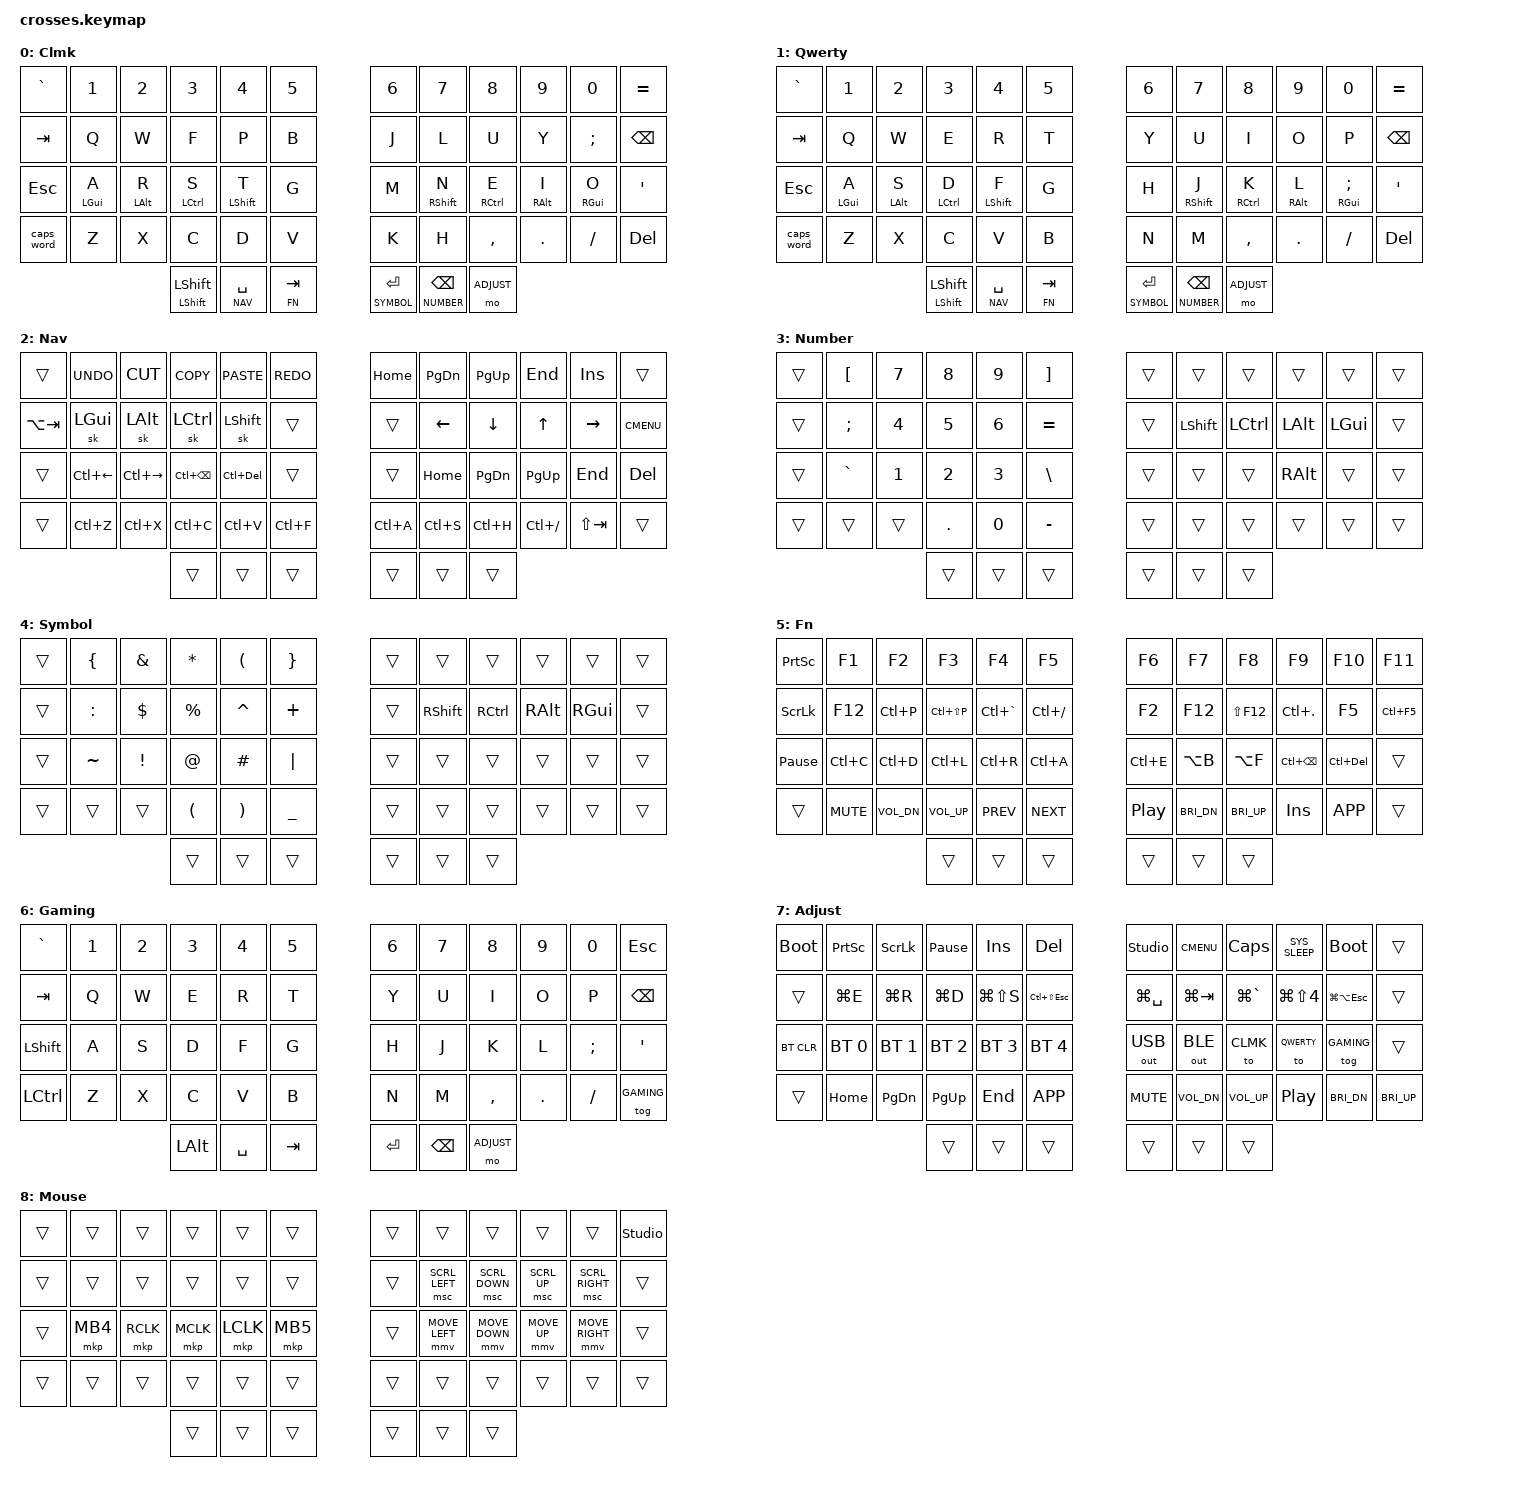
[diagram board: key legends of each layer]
#include <behaviors.dtsi>
#include <dt-bindings/zmk/bt.h>
#include <dt-bindings/zmk/keys.h>
#include <dt-bindings/zmk/outputs.h>
#include <dt-bindings/zmk/pointing.h>

#define CLMK 0
#define QWERTY 1
#define NAV 2
#define NUMBER 3
#define SYMBOL 4
#define FN 5
#define GAMING 6
#define ADJUST 7
#define MOUSE 8

#define ___ &trans
#define XXX &none

&caps_word {
    continue-list = <MINUS UNDERSCORE BACKSPACE DELETE>;
};

&lt {
    flavor = "balanced";
    tapping-term-ms = <200>;
    quick-tap-ms = <175>;
};

&mt {
    flavor = "tap-preferred";
    tapping-term-ms = <220>;
    quick-tap-ms = <175>;
};

&sk {
    release-after-ms = <900>;
    quick-release;
};

/ {
    behaviors {
        hml: homerow_mod_left {
            compatible = "zmk,behavior-hold-tap";
            #binding-cells = <2>;
            flavor = "balanced";
            tapping-term-ms = <220>;
            quick-tap-ms = <175>;
            require-prior-idle-ms = <150>;
            hold-trigger-on-release;
            bindings = <&kp>, <&kp>;
            hold-trigger-key-positions = <6 7 8 9 10 11 18 19 20 21 22 23 30 31 32 33 34 35 42 43 44 45 46 47 51 52 53>;
        };

        hmr: homerow_mod_right {
            compatible = "zmk,behavior-hold-tap";
            #binding-cells = <2>;
            flavor = "balanced";
            tapping-term-ms = <220>;
            quick-tap-ms = <175>;
            require-prior-idle-ms = <150>;
            hold-trigger-on-release;
            bindings = <&kp>, <&kp>;
            hold-trigger-key-positions = <0 1 2 3 4 5 12 13 14 15 16 17 24 25 26 27 28 29 36 37 38 39 40 41 48 49 50>;
        };

        magic_shift: magic_shift {
            compatible = "zmk,behavior-hold-tap";
            #binding-cells = <2>;
            flavor = "balanced";
            tapping-term-ms = <200>;
            quick-tap-ms = <175>;
            bindings = <&kp>, <&sk>;
        };
    };

    chosen { zmk,physical-layout = &gggw_crosses_54_layout; };

    keymap {
        compatible = "zmk,keymap";

        clmk_layer {
            display-name = "Clmk";
            bindings = <
                &kp GRAVE      &kp N1        &kp N2        &kp N3        &kp N4          &kp N5        &kp N6       &kp N7          &kp N8        &kp N9       &kp N0         &kp EQUAL
                &kp TAB        &kp Q         &kp W         &kp F         &kp P           &kp B         &kp J        &kp L           &kp U         &kp Y        &kp SEMI       &kp BSPC
                &kp ESC        &hml LGUI A   &hml LALT R   &hml LCTRL S  &hml LSHFT T    &kp G         &kp M        &hmr RSHFT N    &hmr RCTRL E  &hmr RALT I  &hmr RGUI O    &kp SQT
                &caps_word     &kp Z         &kp X         &kp C         &kp D           &kp V         &kp K        &kp H           &kp COMMA     &kp DOT      &kp FSLH       &kp DEL
                                                            &magic_shift LSHFT LSHFT     &lt NAV SPACE &lt FN TAB   &lt SYMBOL RET  &lt NUMBER BSPC &mo ADJUST
            >;
        };

        qwerty_layer {
            display-name = "Qwerty";
            bindings = <
                &kp GRAVE      &kp N1        &kp N2        &kp N3        &kp N4          &kp N5        &kp N6       &kp N7          &kp N8        &kp N9       &kp N0         &kp EQUAL
                &kp TAB        &kp Q         &kp W         &kp E         &kp R           &kp T         &kp Y        &kp U           &kp I         &kp O        &kp P          &kp BSPC
                &kp ESC        &hml LGUI A   &hml LALT S   &hml LCTRL D  &hml LSHFT F    &kp G         &kp H        &hmr RSHFT J    &hmr RCTRL K  &hmr RALT L  &hmr RGUI SEMI &kp SQT
                &caps_word     &kp Z         &kp X         &kp C         &kp V           &kp B         &kp N        &kp M           &kp COMMA     &kp DOT      &kp FSLH       &kp DEL
                                                            &magic_shift LSHFT LSHFT     &lt NAV SPACE &lt FN TAB   &lt SYMBOL RET  &lt NUMBER BSPC &mo ADJUST
            >;
        };

        nav_layer {
            display-name = "Nav";
            bindings = <
                ___            &kp K_UNDO    &kp K_CUT     &kp K_COPY    &kp K_PASTE     &kp K_REDO    &kp HOME     &kp PG_DN       &kp PG_UP     &kp END      &kp INS        ___
                &kp LA(TAB)    &sk LGUI      &sk LALT      &sk LCTRL     &sk LSHFT       ___           ___          &kp LEFT        &kp DOWN      &kp UP       &kp RIGHT      &kp K_CMENU
                ___            &kp LC(LEFT)  &kp LC(RIGHT) &kp LC(BSPC)  &kp LC(DEL)     ___           ___          &kp HOME        &kp PG_DN     &kp PG_UP    &kp END        &kp DEL
                ___            &kp LC(Z)     &kp LC(X)     &kp LC(C)     &kp LC(V)       &kp LC(F)     &kp LC(A)    &kp LC(S)       &kp LC(H)     &kp LC(FSLH) &kp LS(TAB)    ___
                                                            ___                       ___           ___          ___             ___           ___
            >;
        };

        number_layer {
            display-name = "Number";
            bindings = <
                ___            &kp LBKT      &kp N7        &kp N8        &kp N9          &kp RBKT      ___          ___            ___          ___         ___            ___
                ___            &kp SEMI      &kp N4        &kp N5        &kp N6          &kp EQUAL     ___          &kp LSHFT      &kp LCTRL    &kp LALT    &kp LGUI       ___
                ___            &kp GRAVE     &kp N1        &kp N2        &kp N3          &kp BSLH      ___          ___            ___          &kp RALT    ___            ___
                ___            ___           ___           &kp DOT       &kp N0          &kp MINUS     ___          ___            ___          ___         ___            ___
                                                            ___                       ___           ___          ___             ___           ___
            >;
        };

        symbol_layer {
            display-name = "Symbol";
            bindings = <
                ___            &kp LBRC      &kp AMPS      &kp ASTRK     &kp LPAR        &kp RBRC      ___          ___            ___          ___         ___            ___
                ___            &kp COLON     &kp DLLR      &kp PRCNT     &kp CARET       &kp PLUS      ___          &kp RSHFT      &kp RCTRL    &kp RALT    &kp RGUI       ___
                ___            &kp TILDE     &kp EXCL      &kp AT        &kp HASH        &kp PIPE      ___          ___            ___          ___         ___            ___
                ___            ___           ___           &kp LPAR      &kp RPAR        &kp UNDER     ___          ___            ___          ___         ___            ___
                                                            ___                       ___           ___          ___             ___           ___
            >;
        };

        fn_layer {
            display-name = "Fn";
            bindings = <
                &kp PSCRN      &kp F1        &kp F2        &kp F3        &kp F4          &kp F5        &kp F6       &kp F7         &kp F8       &kp F9      &kp F10        &kp F11
                &kp SLCK       &kp F12       &kp LC(P)     &kp LC(LS(P)) &kp LC(GRAVE)   &kp LC(FSLH)  &kp F2       &kp F12        &kp LS(F12)  &kp LC(DOT) &kp F5         &kp LC(F5)
                &kp PAUSE_BREAK &kp LC(C)    &kp LC(D)     &kp LC(L)     &kp LC(R)       &kp LC(A)     &kp LC(E)    &kp LA(B)      &kp LA(F)    &kp LC(BSPC)&kp LC(DEL)    ___
                ___            &kp C_MUTE    &kp C_VOL_DN  &kp C_VOL_UP  &kp C_PREV      &kp C_NEXT    &kp C_PLAY_PAUSE &kp C_BRI_DN &kp C_BRI_UP &kp INS     &kp K_APP      ___
                                                            ___                       ___           ___          ___             ___           ___
            >;
        };

        gaming_layer {
            display-name = "Gaming";
            bindings = <
                &kp GRAVE      &kp N1        &kp N2        &kp N3        &kp N4          &kp N5        &kp N6       &kp N7         &kp N8       &kp N9      &kp N0         &kp ESC
                &kp TAB        &kp Q         &kp W         &kp E         &kp R           &kp T         &kp Y        &kp U          &kp I        &kp O       &kp P          &kp BSPC
                &kp LSHFT      &kp A         &kp S         &kp D         &kp F           &kp G         &kp H        &kp J          &kp K        &kp L       &kp SEMI       &kp SQT
                &kp LCTRL      &kp Z         &kp X         &kp C         &kp V           &kp B         &kp N        &kp M          &kp COMMA    &kp DOT     &kp FSLH       &tog GAMING
                                                            &kp LALT                  &kp SPACE     &kp TAB      &kp RET        &kp BSPC      &mo ADJUST
            >;
        };

        adjust_layer {
            display-name = "Adjust";
            bindings = <
                &bootloader    &kp PSCRN     &kp SLCK      &kp PAUSE_BREAK &kp INS       &kp DEL       &studio_unlock &kp K_CMENU   &kp CAPSLOCK &kp SYS_SLEEP &bootloader   ___
                ___            &kp LG(E)     &kp LG(R)     &kp LG(D)       &kp LG(LS(S)) &kp LC(LS(ESC)) &kp LG(SPACE) &kp LG(TAB)   &kp LG(GRAVE) &kp LG(LS(N4)) &kp LG(LA(ESC)) ___
                &bt BT_CLR     &bt BT_SEL 0  &bt BT_SEL 1  &bt BT_SEL 2    &bt BT_SEL 3  &bt BT_SEL 4  &out OUT_USB  &out OUT_BLE  &to CLMK      &to QWERTY    &tog GAMING   ___
                ___            &kp HOME      &kp PG_DN     &kp PG_UP       &kp END       &kp K_APP     &kp C_MUTE    &kp C_VOL_DN  &kp C_VOL_UP  &kp C_PLAY_PAUSE &kp C_BRI_DN &kp C_BRI_UP
                                                            ___                       ___           ___          ___             ___           ___
            >;
        };

        mouse_layer {
            display-name = "Mouse";
            bindings = <
                ___            ___           ___           ___           ___            ___           ___          ___            ___          ___         ___            &studio_unlock
                ___            ___           ___           ___           ___            ___           ___          &msc SCRL_LEFT  &msc SCRL_DOWN &msc SCRL_UP &msc SCRL_RIGHT ___
                ___            &mkp MB4      &mkp RCLK     &mkp MCLK     &mkp LCLK      &mkp MB5     ___          &mmv MOVE_LEFT &mmv MOVE_DOWN &mmv MOVE_UP &mmv MOVE_RIGHT ___
                ___            ___           ___           ___           ___            ___           ___          ___            ___          ___         ___            ___
                                                            ___                       ___           ___          ___             ___           ___
            >;
        };
    };
};
